VERSION ""

NS_ :

BS_:

BU_: MotGenerator

BO_ 512 MtxMsg1: 8 MotGenerator
 SG_ M_MotA : 0|16@0+ (1,0) [0|65535] "" MotGenerator
 SG_ M_MotB : 16|16@0+ (1,0) [0|65535] "" MotGenerator
 SG_ M_MotC : 32|16@0+ (1,0) [0|65535] "" MotGenerator
 SG_ M_MotD : 48|16@0+ (1,0) [0|65535] "" MotGenerator

BO_ 513 MtxMsg2: 8 MotGenerator
 SG_ M_MotU8a : 0|8@0+ (1,0) [0|255] "" MotGenerator
 SG_ M_MotU12 : 8|12@0+ (1,0) [0|4095] "" MotGenerator
 SG_ M_MotU4a : 20|4@0+ (1,0) [0|15] "" MotGenerator
 SG_ M_MotU4b : 24|4@0+ (1,0) [0|15] "" MotGenerator
 SG_ M_MotU2 : 28|2@0+ (1,0) [0|3] "" MotGenerator
 SG_ M_MotBit1 : 32|1@0+ (1,0) [0|1] "" MotGenerator
 SG_ M_MotBit0 : 33|1@0+ (1,0) [0|1] "" MotGenerator
 SG_ M_MotS8 : 40|8@0- (1,0) [-128|127] "" MotGenerator
 SG_ M_MotU16u : 48|16@0+ (1,0) [0|65535] "" MotGenerator

BO_ 514 MtxMsg3: 8 MotGenerator
 SG_ M_MotU32 : 0|32@0+ (1,0) [0|4294967295] "" MotGenerator
 SG_ M_MotS16 : 32|16@0- (1,0) [-32768|32767] "" MotGenerator
 SG_ M_MotS8b : 48|8@0- (1,0) [-128|127] "" MotGenerator
 SG_ M_MotU8c : 56|8@0+ (1,0) [0|255] "" MotGenerator

BO_ 515 MtxMsg4: 8 MotGenerator
 SG_ M_MotScaled : 0|16@0+ (0.1,-40) [-40|6513.5] "degC" MotGenerator
 SG_ M_MotEnum : 16|8@0+ (1,0) [0|255] "" MotGenerator
 SG_ M_MotU40 : 24|40@0+ (1,0) [0|1099511627775] "" MotGenerator

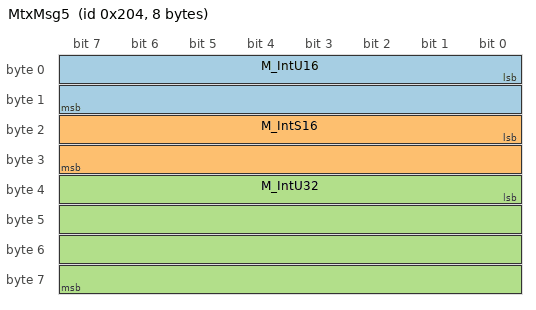
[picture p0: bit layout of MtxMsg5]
BO_ 516 MtxMsg5: 8 MotGenerator
 SG_ M_IntU16 : 0|16@1+ (1,0) [0|65535] "" MotGenerator
 SG_ M_IntS16 : 16|16@1- (1,0) [-32768|32767] "" MotGenerator
 SG_ M_IntU32 : 32|32@1+ (1,0) [0|4294967295] "" MotGenerator

CM_ BO_ 512 "Motorola matrix msg 1: four aligned 16-bit big-endian signals";
CM_ BO_ 513 "Motorola matrix msg 2: unaligned 4/2/1-bit + 12-bit + signed 8-bit";
CM_ BO_ 514 "Motorola matrix msg 3: 32-bit + signed 16/8-bit";
CM_ BO_ 515 "Motorola matrix msg 4: scaled/offset + enum + 40-bit across 5 bytes";
CM_ BO_ 516 "Intel control group: little-endian counterparts";
CM_ SG_ 512 M_MotA "big-endian bytes 0-1";
CM_ SG_ 515 M_MotScaled "physical = raw*0.1 - 40";

BA_DEF_ "BusType" STRING ;
BA_DEF_ BO_ "GenMsgCycleTime" INT 0 65535;

BA_ "BusType" "CAN";
BA_ "GenMsgCycleTime" BO_ 512 10;
BA_ "GenMsgCycleTime" BO_ 513 10;
BA_ "GenMsgCycleTime" BO_ 514 10;
BA_ "GenMsgCycleTime" BO_ 515 10;
BA_ "GenMsgCycleTime" BO_ 516 10;

VAL_ 515 M_MotEnum 0 "IDLE" 86 "RUN" 100 "FULL" ;
